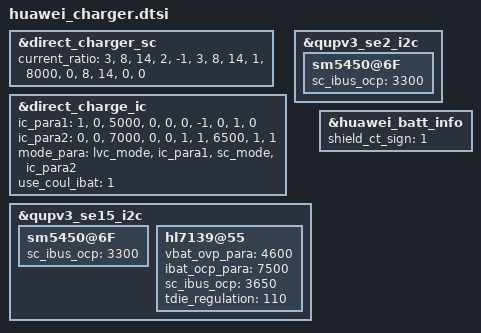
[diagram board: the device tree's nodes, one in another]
&direct_charger_sc {
	current_ratio =
		"3", "8", "14", "2", "-1",
		"3", "8", "14", "1", "8000",
		"0", "8", "14", "0", "0";
};

&direct_charge_ic {
	/* The IC_PARA table is used to find the relationship between chip and path */
	/* the chip's current passing capacity */
	/* and the sampling points of battery voltage and current */
	/* ic_index path_index max_ibat ibat_sample_point vbat_sample_point */
	/* ic_index  path_index  max_ibat  ibat_sample_point  vbat_sample_point */
	ic_para1 =
		"1", "0", "5000", "0", "0",
		"0", "-1", "0", "1", "0";
	ic_para2 =
		"0", "0", "7000", "0", "0",
		"1", "1", "6500", "1", "1";
	mode_para =
		"lvc_mode", "ic_para1",
		"sc_mode", "ic_para2";
	use_coul_ibat = <1>;
	status = "ok";
};

&qupv3_se2_i2c {
	sm5450@6F {
		sc_ibus_ocp = <3300>;
	};
};

&qupv3_se15_i2c {
	sm5450@6F {
		sc_ibus_ocp = <3300>;
	};
	hl7139@55 {
		vbat_ovp_para = <4600>;
		ibat_ocp_para = <7500>;
		sc_ibus_ocp = <3650>;
		tdie_regulation = <110>;
	};
};

&huawei_batt_info {
    shield_ct_sign = <1>;
};
